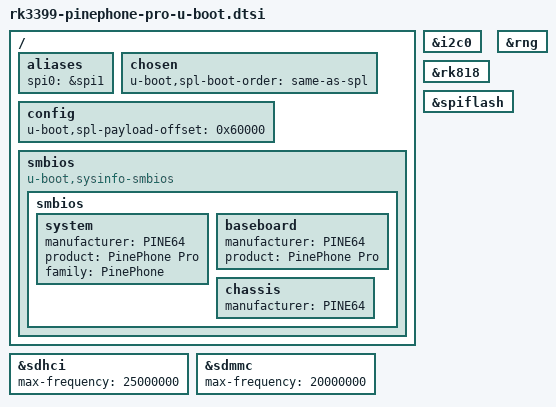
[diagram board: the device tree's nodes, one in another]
// SPDX-License-Identifier: GPL-2.0+
/*
 * Copyright (C) 2022 Peter Robinson <pbrobinson at gmail.com>
 */

#include "rk3399-u-boot.dtsi"
#include "rk3399-sdram-lpddr4-100.dtsi"

/ {
	aliases {
		spi0 = &spi1;
	};

	chosen {
		u-boot,spl-boot-order = "same-as-spl", &spiflash, &sdhci, &sdmmc;
	};

	config {
		u-boot,spl-payload-offset = <0x60000>; /* @ 384KB */
	};
	smbios {
		compatible = "u-boot,sysinfo-smbios";
		
		smbios {
			system {
				manufacturer = "PINE64";
				product = "PinePhone Pro";
				family = "PinePhone";
			};

			baseboard {
				manufacturer = "PINE64";
				product = "PinePhone Pro";
			};

			chassis {
				manufacturer = "PINE64";
			};
		};
	};
};

&i2c0 {
	bootph-all;
};

&rk818 {
	bootph-all;
};

&rng {
	status = "okay";
};

&sdhci {
	max-frequency = <25000000>;
	bootph-all;
};

&sdmmc {
	max-frequency = <20000000>;
	bootph-all;
};

&spiflash {
	bootph-all;
};
